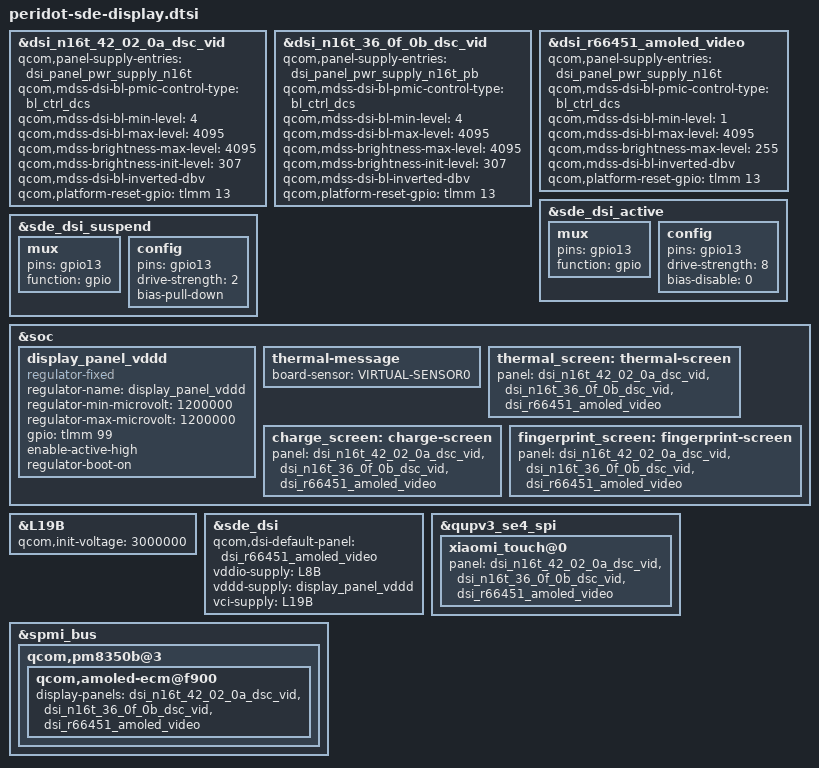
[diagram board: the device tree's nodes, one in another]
#include "cliffs-sde-display-mtp.dtsi"
#include "dsi-panel-r66451-dsc-fhd-plus-video.dtsi"

&dsi_n16t_42_02_0a_dsc_vid {
	qcom,panel-supply-entries = <&dsi_panel_pwr_supply_n16t>;
	qcom,mdss-dsi-bl-pmic-control-type = "bl_ctrl_dcs";
	qcom,mdss-dsi-bl-min-level = <4>;
	qcom,mdss-dsi-bl-max-level = <4095>;
	qcom,mdss-brightness-max-level = <4095>;
	qcom,mdss-brightness-init-level = <307>;
	qcom,mdss-dsi-bl-inverted-dbv;
	qcom,platform-reset-gpio = <&tlmm 13 0>;
};

&dsi_n16t_36_0f_0b_dsc_vid {
	qcom,panel-supply-entries = <&dsi_panel_pwr_supply_n16t_pb>;
	qcom,mdss-dsi-bl-pmic-control-type = "bl_ctrl_dcs";
	qcom,mdss-dsi-bl-min-level = <4>;
	qcom,mdss-dsi-bl-max-level = <4095>;
	qcom,mdss-brightness-max-level = <4095>;
	qcom,mdss-brightness-init-level = <307>;
	qcom,mdss-dsi-bl-inverted-dbv;
	qcom,platform-reset-gpio = <&tlmm 13 0>;
};

&dsi_r66451_amoled_video {
	qcom,panel-supply-entries = <&dsi_panel_pwr_supply_n16t>;
	qcom,mdss-dsi-bl-pmic-control-type = "bl_ctrl_dcs";
	qcom,mdss-dsi-bl-min-level = <1>;
	qcom,mdss-dsi-bl-max-level = <4095>;
	qcom,mdss-brightness-max-level = <255>;
	qcom,mdss-dsi-bl-inverted-dbv;
	qcom,platform-reset-gpio = <&tlmm 13 0>;
};

&sde_dsi_active {
	mux {
		pins = "gpio13";
		function = "gpio";
	};

	config {
		pins = "gpio13";
		drive-strength = <8>;   /* 8 mA */
		bias-disable = <0>;   /* no pull */
	};
};

&sde_dsi_suspend {
	mux {
		pins = "gpio13";
		function = "gpio";
	};

	config {
		pins = "gpio13";
		drive-strength = <2>;   /* 2 mA */
		bias-pull-down;         /* PULL DOWN */
	};
};

&soc {

	display_panel_vddd: display_panel_vddd {
		compatible = "regulator-fixed";
		regulator-name = "display_panel_vddd";
		regulator-min-microvolt = <1200000>;
		regulator-max-microvolt = <1200000>;
		gpio = <&tlmm 99 0>;
		enable-active-high;
		regulator-boot-on;
	};

};
&L19B {
	qcom,init-voltage = <3000000>;
};
&sde_dsi {
	qcom,dsi-default-panel = <&dsi_r66451_amoled_video>;
	vddio-supply = <&L8B>;
	vddd-supply = <&display_panel_vddd>;
	vci-supply = <&L19B>;
};
&qupv3_se4_spi {
	xiaomi_touch@0 {
		panel = <&dsi_n16t_42_02_0a_dsc_vid
			&dsi_n16t_36_0f_0b_dsc_vid
			&dsi_r66451_amoled_video>;
	};
};
&soc {
	thermal-message {
		board-sensor = "VIRTUAL-SENSOR0";
	};
	thermal_screen: thermal-screen {
		panel = <&dsi_n16t_42_02_0a_dsc_vid
		&dsi_n16t_36_0f_0b_dsc_vid
		&dsi_r66451_amoled_video>;
	};
	charge_screen: charge-screen {
		panel = <&dsi_n16t_42_02_0a_dsc_vid
		&dsi_n16t_36_0f_0b_dsc_vid
		&dsi_r66451_amoled_video>;
	};
	fingerprint_screen: fingerprint-screen {
		panel = <&dsi_n16t_42_02_0a_dsc_vid
		&dsi_n16t_36_0f_0b_dsc_vid
		&dsi_r66451_amoled_video>;
	};
};
&spmi_bus {
	qcom,pm8350b@3 {
		qcom,amoled-ecm@f900 {
			display-panels = <&dsi_n16t_42_02_0a_dsc_vid
			&dsi_n16t_36_0f_0b_dsc_vid
			&dsi_r66451_amoled_video>;
		};
	};
};
